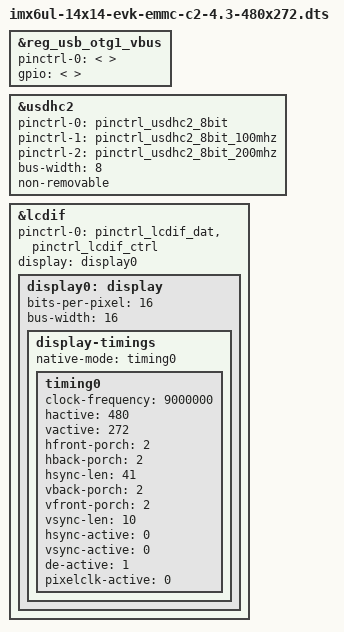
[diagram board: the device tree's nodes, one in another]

/*
 * Copyright (C) 2016 Freescale Semiconductor, Inc.
 *
 * This program is free software; you can redistribute it and/or modify
 * it under the terms of the GNU General Public License version 2 as
 * published by the Free Software Foundation.
 */

#include "imx6ul-14x14-evk-c2.dts"

&reg_usb_otg1_vbus {
        pinctrl-0 = < >;
        gpio = < >;
};

&usdhc2 {
	pinctrl-names = "default", "state_100mhz", "state_200mhz";
	pinctrl-0 = <&pinctrl_usdhc2_8bit>;
	pinctrl-1 = <&pinctrl_usdhc2_8bit_100mhz>;
	pinctrl-2 = <&pinctrl_usdhc2_8bit_200mhz>;
	bus-width = <8>;
	non-removable;
	status = "okay";
};
&lcdif {
	pinctrl-names = "default";
	pinctrl-0 = <&pinctrl_lcdif_dat
		&pinctrl_lcdif_ctrl>;
	display = <&display0>;
	status = "okay";

	display0: display {
		bits-per-pixel = <16>;
		bus-width = <16>;

		display-timings {
			native-mode = <&timing0>;
			timing0: timing0 {
			clock-frequency = <9000000>;
			hactive = <480>;
			vactive = <272>;
			hfront-porch = <2>;
			hback-porch = <2>;
			hsync-len = <41>;
			vback-porch = <2>;
			vfront-porch = <2>;
			vsync-len = <10>;

			hsync-active = <0>;
			vsync-active = <0>;
			de-active = <1>;
			pixelclk-active = <0>;
			};
		};
	};
};
